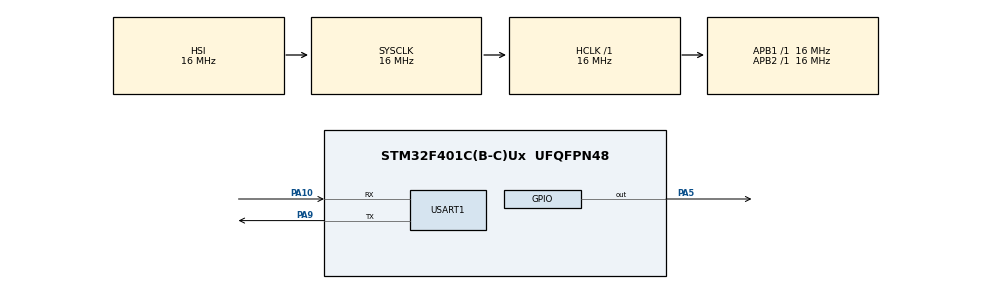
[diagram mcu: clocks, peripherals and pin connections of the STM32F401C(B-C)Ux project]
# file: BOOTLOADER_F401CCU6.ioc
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Mcu.Family=STM32F4
Mcu.Name=STM32F401C(B-C)Ux
Mcu.Package=UFQFPN48
NVIC.PriorityGroup=NVIC_PRIORITYGROUP_4
PA10.Mode=Asynchronous
PA10.Signal=USART1_RX
PA13.Mode=Serial_Wire
PA13.Signal=SYS_JTMS-SWDIO
PA14.Mode=Serial_Wire
PA14.Signal=SYS_JTCK-SWCLK
PA5.Signal=GPIO_Output
PA9.Mode=Asynchronous
PA9.Signal=USART1_TX
PH0\ -\ OSC_IN.Mode=HSE-External-Oscillator
PH0\ -\ OSC_IN.Signal=RCC_OSC_IN
PH1\ -\ OSC_OUT.Mode=HSE-External-Oscillator
PH1\ -\ OSC_OUT.Signal=RCC_OSC_OUT
ProjectManager.HeapSize=0x200
ProjectManager.StackSize=0x400
ProjectManager.TargetToolchain=STM32CubeIDE
RCC.AHBFreq_Value=16000000
RCC.APB1Freq_Value=16000000
RCC.APB2Freq_Value=16000000
RCC.CortexFreq_Value=16000000
RCC.HSE_VALUE=25000000
RCC.HSI_VALUE=16000000
RCC.LSE_VALUE=32768
RCC.SYSCLKFreq_VALUE=16000000
RCC.VCOOutputFreq_Value=192000000
USART1.VirtualMode=VM_ASYNC
board=custom

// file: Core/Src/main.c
/* USER CODE BEGIN Header */
/**
  ******************************************************************************
  * @file           : main.c
  * @brief          : Main program body
  ******************************************************************************
  * @attention
  *
  * Copyright (c) 2026 STMicroelectronics.
  * All rights reserved.
  *
  * This software is licensed under terms that can be found in the LICENSE file
  * in the root directory of this software component.
  * If no LICENSE file comes with this software, it is provided AS-IS.
  *
  ******************************************************************************
  */
/* USER CODE END Header */

#include "main.h"
#include <stdio.h>
#include <string.h>
#include "flash_layout.h"
#include <application_header.h>
#include "bootloader_jump.h"
#include "bl_ota.h"

/* USER CODE BEGIN PD */
void JumpToApplication(void);
int bootloader_is_app_valid(void);
/* USER CODE END PD */

UART_HandleTypeDef huart1;

void SystemClock_Config(void);
static void MX_GPIO_Init(void);
static void MX_USART1_UART_Init(void);

/* USER CODE BEGIN 0 */
static uint32_t mem_base = OTA_START_ADDR;  // used with external or dual flash
static uint32_t mem_cursor = 0;
static uint32_t ota_image_total_size = 16;  // expected OTA Header size

void ota_mem_set_total_size(uint32_t size)
{
    ota_image_total_size = size;
}

int ota_read_mem(uint8_t *buf, uint32_t len)
{
    if (mem_cursor + len > ota_image_total_size)
        return -1;

    uint8_t *flash_ptr = (uint8_t *)(mem_base + mem_cursor);

    memcpy(buf, flash_ptr, len);

    mem_cursor += len;
    return 0;
}
/* USER CODE END 0 */

int main(void)
{

  /* MCU Configuration--------------------------------------------------------*/

  /* Reset of all peripherals, Initializes the Flash interface and the Systick. */
  HAL_Init();

  /* Configure the system clock */
  SystemClock_Config();

  /* Initialize all configured peripherals */
  MX_GPIO_Init();
  MX_USART1_UART_Init();
  /* USER CODE BEGIN 2 */
   HAL_Delay(100);
   char data[] = "Inside Bootloader!!\r\n";
   HAL_UART_Transmit(&huart1, (uint8_t *)data, strlen(data), 1000);

   if (check_ota_request() == 0)
   {
 	  HAL_UART_Transmit(&huart1, (uint8_t *)"Performing OTA...\n", 18, 100);

 	  ota_stream_t stream =
 	  {
 	      .read = ota_read_mem,
 	      .set_total_size = ota_mem_set_total_size
 	  };

 	  bl_ota_ctx_t ctx;
 	 if (bl_ota_run(&ctx, &stream) != 0)
 	 {
 		 HAL_UART_Transmit(&huart1, (uint8_t *)"OTA Failed...\n", 14, 100);
 		  while (1)
 		  {
 			  HAL_GPIO_TogglePin(GPIOA, GPIO_PIN_5);
 			  HAL_Delay(250);
 		  }
 	 }
 	 else {
 		 HAL_UART_Transmit(&huart1, (uint8_t *)"OTA Flashed Successfully, Jumping to app...\n", 44, 100);
 	 }

   }

   int err = bootloader_is_app_valid();

  /* USER CODE END 2 */
   if (err != 0)
    {
  	  HAL_UART_Transmit(&huart1, (uint8_t *)"Failed to Jump!!\r\n", 18, 100);
  	  switch(err){
	  case 1:
		  HAL_UART_Transmit(&huart1, (uint8_t *)"MAGIC ERROR!!\r\n", 15, 100);
		  break;

	  case 2:
		  HAL_UART_Transmit(&huart1, (uint8_t *)"RESET ERROR!!\r\n", 15, 100);
		  break;

	  case 3:
		  HAL_UART_Transmit(&huart1, (uint8_t *)"SIZE ERROR!!\r\n", 14, 100);
		  break;

	  case 4:
		  HAL_UART_Transmit(&huart1, (uint8_t *)"CRC ERROR!!\r\n", 13, 100);
		  break;

	  default:
		  HAL_UART_Transmit(&huart1, (uint8_t *)"ERROR!!\r\n", 9, 100);
		  break;

  	  }
  	  while (1)
  	  {
  		  HAL_GPIO_TogglePin(GPIOC, GPIO_PIN_13);
  		  HAL_Delay(3000);
  	  }
    }

   JumpToApplication();
  /* Infinite loop */
  while (1)
  {
	  for( int i = 0; i < 21; i++ )
	 	  {
	 		  HAL_GPIO_TogglePin(GPIOC, GPIO_PIN_13);
	 		  HAL_Delay(500);

	 	  }
	          HAL_Delay(1000);

  }
}

void SystemClock_Config(void)
{
  RCC_OscInitTypeDef RCC_OscInitStruct = {0};
  RCC_ClkInitTypeDef RCC_ClkInitStruct = {0};

  /** Configure the main internal regulator output voltage
  */
  __HAL_RCC_PWR_CLK_ENABLE();
  __HAL_PWR_VOLTAGESCALING_CONFIG(PWR_REGULATOR_VOLTAGE_SCALE2);

  /** Initializes the RCC Oscillators according to the specified parameters
  * in the RCC_OscInitTypeDef structure.
  */
  RCC_OscInitStruct.OscillatorType = RCC_OSCILLATORTYPE_HSI;
  RCC_OscInitStruct.HSIState = RCC_HSI_ON;
  RCC_OscInitStruct.HSICalibrationValue = RCC_HSICALIBRATION_DEFAULT;
  RCC_OscInitStruct.PLL.PLLState = RCC_PLL_NONE;
  if (HAL_RCC_OscConfig(&RCC_OscInitStruct) != HAL_OK)
  {
    Error_Handler();
  }

  /** Initializes the CPU, AHB and APB buses clocks
  */
  RCC_ClkInitStruct.ClockType = RCC_CLOCKTYPE_HCLK|RCC_CLOCKTYPE_SYSCLK
                              |RCC_CLOCKTYPE_PCLK1|RCC_CLOCKTYPE_PCLK2;
  RCC_ClkInitStruct.SYSCLKSource = RCC_SYSCLKSOURCE_HSI;
  RCC_ClkInitStruct.AHBCLKDivider = RCC_SYSCLK_DIV1;
  RCC_ClkInitStruct.APB1CLKDivider = RCC_HCLK_DIV1;
  RCC_ClkInitStruct.APB2CLKDivider = RCC_HCLK_DIV1;

  if (HAL_RCC_ClockConfig(&RCC_ClkInitStruct, FLASH_LATENCY_0) != HAL_OK)
  {
    Error_Handler();
  }
}

static void MX_USART1_UART_Init(void)
{

  huart1.Instance = USART1;
  huart1.Init.BaudRate = 115200;
  huart1.Init.WordLength = UART_WORDLENGTH_8B;
  huart1.Init.StopBits = UART_STOPBITS_1;
  huart1.Init.Parity = UART_PARITY_NONE;
  huart1.Init.Mode = UART_MODE_TX_RX;
  huart1.Init.HwFlowCtl = UART_HWCONTROL_NONE;
  huart1.Init.OverSampling = UART_OVERSAMPLING_16;
  if (HAL_UART_Init(&huart1) != HAL_OK)
  {
    Error_Handler();
  }

}

static void MX_GPIO_Init(void)
{
  GPIO_InitTypeDef GPIO_InitStruct = {0};

  /* GPIO Ports Clock Enable */
  __HAL_RCC_GPIOC_CLK_ENABLE();
  __HAL_RCC_GPIOH_CLK_ENABLE();

  /*Configure GPIO pin Output Level */
  HAL_GPIO_WritePin(GPIOC, GPIO_PIN_13, GPIO_PIN_RESET);

  /*Configure GPIO pin : PC13 */
  GPIO_InitStruct.Pin = GPIO_PIN_13;
  GPIO_InitStruct.Mode = GPIO_MODE_OUTPUT_PP;
  GPIO_InitStruct.Pull = GPIO_NOPULL;
  GPIO_InitStruct.Speed = GPIO_SPEED_FREQ_LOW;
  HAL_GPIO_Init(GPIOC, &GPIO_InitStruct);

}

void Error_Handler(void)
{
  __disable_irq();
  while (1)
  {
  }
}
